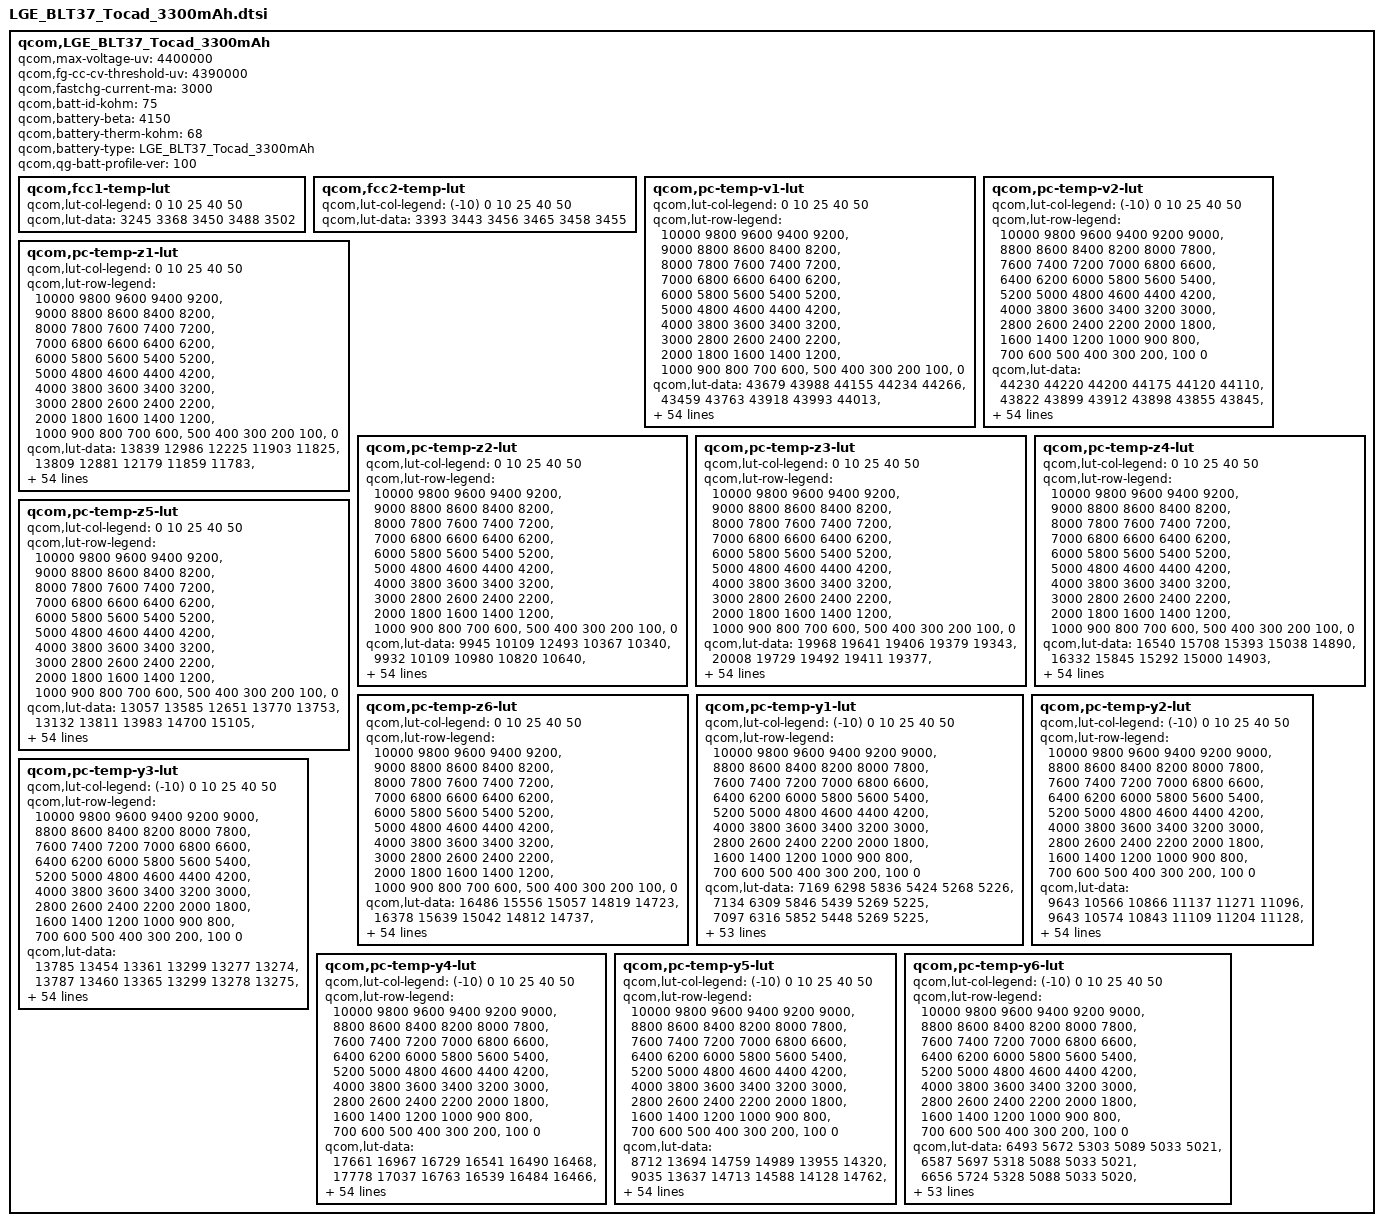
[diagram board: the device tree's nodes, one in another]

qcom,LGE_BLT37_Tocad_3300mAh {
    /* 3733478_LGE_CV7Atocad_3500mAh_averaged_MasterSlave_Dec3rd2018 */
    qcom,max-voltage-uv = <4400000>;
    qcom,fg-cc-cv-threshold-uv = <4390000>;
    qcom,fastchg-current-ma = <3000>;
    qcom,batt-id-kohm = <75>;
    qcom,battery-beta = <4150>;
    qcom,battery-therm-kohm = <68>;
    qcom,battery-type = "LGE_BLT37_Tocad_3300mAh";
    qcom,qg-batt-profile-ver = <100>;

	qcom,fcc1-temp-lut {
		qcom,lut-col-legend = <0 10 25 40 50>;
		qcom,lut-data = <3245 3368 3450 3488 3502>;
	};

	qcom,fcc2-temp-lut {
		qcom,lut-col-legend = <(-10) 0 10 25 40 50>;
		qcom,lut-data = <3393 3443 3456 3465 3458 3455>;
	};

	qcom,pc-temp-v1-lut {
		qcom,lut-col-legend = <0 10 25 40 50>;
		qcom,lut-row-legend = <10000 9800 9600 9400 9200>,
			<9000 8800 8600 8400 8200>,
			<8000 7800 7600 7400 7200>,
			<7000 6800 6600 6400 6200>,
			<6000 5800 5600 5400 5200>,
			<5000 4800 4600 4400 4200>,
			<4000 3800 3600 3400 3200>,
			<3000 2800 2600 2400 2200>,
			<2000 1800 1600 1400 1200>,
			<1000 900 800 700 600>,
			<500 400 300 200 100>,
			<0>;
		qcom,lut-data = <43679 43988 44155 44234 44266>,
			<43459 43763 43918 43993 44013>,
			<43231 43543 43686 43758 43776>,
			<42996 43321 43462 43531 43548>,
			<42760 43090 43238 43311 43329>,
			<42526 42851 43004 43084 43107>,
			<42292 42613 42764 42846 42875>,
			<42063 42372 42523 42604 42638>,
			<41839 42133 42280 42362 42399>,
			<41620 41900 42039 42120 42156>,
			<41405 41671 41803 41881 41915>,
			<41194 41449 41569 41644 41679>,
			<40989 41230 41343 41412 41448>,
			<40790 41019 41124 41187 41221>,
			<40594 40812 40911 40969 40999>,
			<40405 40611 40706 40758 40784>,
			<40223 40419 40507 40554 40579>,
			<40048 40248 40317 40357 40381>,
			<39887 40091 40141 40174 40194>,
			<39746 39927 39971 40002 40019>,
			<39606 39754 39792 39822 39840>,
			<39447 39569 39601 39617 39638>,
			<39275 39349 39404 39405 39428>,
			<39104 39078 39185 39209 39232>,
			<38931 38867 38965 39020 39043>,
			<38764 38756 38816 38862 38879>,
			<38643 38673 38722 38738 38747>,
			<38557 38597 38641 38633 38634>,
			<38490 38527 38551 38534 38531>,
			<38435 38461 38462 38441 38437>,
			<38390 38398 38385 38357 38350>,
			<38351 38338 38315 38281 38269>,
			<38315 38284 38253 38211 38194>,
			<38281 38234 38198 38150 38128>,
			<38249 38189 38149 38098 38071>,
			<38219 38151 38102 38045 38011>,
			<38187 38120 38060 37988 37942>,
			<38142 38081 38015 37927 37866>,
			<38077 38014 37950 37856 37786>,
			<37996 37921 37862 37772 37702>,
			<37894 37819 37762 37675 37607>,
			<37764 37700 37648 37562 37493>,
			<37615 37561 37515 37429 37359>,
			<37450 37393 37350 37267 37194>,
			<37312 37234 37195 37117 37046>,
			<37208 37131 37094 37022 36961>,
			<37169 37103 37069 37000 36938>,
			<37138 37084 37048 36986 36922>,
			<37108 37056 37032 36968 36905>,
			<37051 37009 36988 36921 36854>,
			<36867 36812 36771 36673 36582>,
			<36432 36360 36332 36236 36144>,
			<35856 35773 35759 35660 35571>,
			<35059 34956 34979 34876 34786>,
			<33693 33554 33762 33655 33564>,
			<30000 30000 30000 30000 30000>;
	};

	qcom,pc-temp-v2-lut {
		qcom,lut-col-legend = <(-10) 0 10 25 40 50>;
		qcom,lut-row-legend = <10000 9800 9600 9400 9200 9000>,
			<8800 8600 8400 8200 8000 7800>,
			<7600 7400 7200 7000 6800 6600>,
			<6400 6200 6000 5800 5600 5400>,
			<5200 5000 4800 4600 4400 4200>,
			<4000 3800 3600 3400 3200 3000>,
			<2800 2600 2400 2200 2000 1800>,
			<1600 1400 1200 1000 900 800>,
			<700 600 500 400 300 200>,
			<100 0>;
		qcom,lut-data = <44230 44220 44200 44175 44120 44110>,
			<43822 43899 43912 43898 43855 43845>,
			<43472 43603 43642 43635 43600 43591>,
			<43195 43337 43390 43389 43359 43351>,
			<42984 43102 43160 43163 43133 43125>,
			<42776 42869 42930 42936 42905 42899>,
			<42520 42625 42688 42697 42668 42663>,
			<42242 42379 42443 42455 42428 42424>,
			<41983 42132 42200 42213 42188 42185>,
			<41740 41887 41959 41972 41949 41947>,
			<41518 41641 41722 41735 41713 41712>,
			<41338 41384 41488 41503 41483 41481>,
			<41189 41127 41259 41276 41257 41255>,
			<41006 40915 41038 41054 41037 41034>,
			<40730 40757 40824 40835 40820 40819>,
			<40406 40597 40616 40624 40611 40611>,
			<40105 40383 40415 40421 40410 40411>,
			<39811 40127 40217 40225 40217 40218>,
			<39538 39877 40009 40036 40030 40032>,
			<39298 39635 39784 39859 39858 39860>,
			<39076 39400 39555 39674 39679 39682>,
			<38862 39181 39331 39445 39456 39461>,
			<38643 38973 39108 39189 39203 39210>,
			<38465 38785 38917 38980 38996 39003>,
			<38353 38617 38757 38817 38837 38845>,
			<38269 38463 38616 38676 38700 38711>,
			<38200 38318 38489 38554 38578 38589>,
			<38141 38178 38376 38446 38472 38481>,
			<38087 38075 38271 38348 38375 38383>,
			<38034 38015 38172 38257 38285 38291>,
			<37983 37968 38082 38174 38203 38206>,
			<37932 37922 37995 38097 38128 38129>,
			<37879 37878 37911 38025 38059 38058>,
			<37824 37834 37845 37957 37991 37986>,
			<37768 37789 37804 37892 37921 37911>,
			<37710 37743 37768 37826 37848 37830>,
			<37649 37691 37726 37752 37758 37731>,
			<37585 37632 37680 37670 37648 37606>,
			<37515 37563 37623 37588 37545 37491>,
			<37438 37481 37549 37511 37458 37402>,
			<37350 37383 37457 37431 37375 37319>,
			<37254 37270 37346 37333 37275 37219>,
			<37152 37131 37207 37212 37156 37097>,
			<37047 36984 37054 37062 37014 36958>,
			<36949 36830 36897 36924 36879 36825>,
			<36856 36729 36794 36880 36848 36796>,
			<36811 36696 36759 36865 36834 36783>,
			<36767 36665 36725 36846 36820 36765>,
			<36720 36616 36675 36817 36790 36735>,
			<36666 36544 36591 36740 36708 36638>,
			<36591 36365 36365 36470 36416 36326>,
			<36426 35956 35907 35988 35933 35837>,
			<36063 35269 35269 35357 35294 35193>,
			<35408 34234 34398 34480 34412 34299>,
			<34365 32611 33014 33140 33063 32918>,
			<32811 29064 27778 28286 28226 28233>;
	};

	qcom,pc-temp-z1-lut {
		qcom,lut-col-legend = <0 10 25 40 50>;
		qcom,lut-row-legend = <10000 9800 9600 9400 9200>,
			<9000 8800 8600 8400 8200>,
			<8000 7800 7600 7400 7200>,
			<7000 6800 6600 6400 6200>,
			<6000 5800 5600 5400 5200>,
			<5000 4800 4600 4400 4200>,
			<4000 3800 3600 3400 3200>,
			<3000 2800 2600 2400 2200>,
			<2000 1800 1600 1400 1200>,
			<1000 900 800 700 600>,
			<500 400 300 200 100>,
			<0>;
		qcom,lut-data = <13839 12986 12225 11903 11825>,
			<13809 12881 12179 11859 11783>,
			<13792 12850 12146 11829 11756>,
			<13780 12833 12124 11816 11747>,
			<13770 12827 12108 11808 11742>,
			<13756 12821 12097 11804 11740>,
			<13736 12814 12088 11802 11740>,
			<13717 12790 12081 11801 11740>,
			<13699 12762 12077 11800 11740>,
			<13681 12755 12074 11800 11741>,
			<13666 12754 12072 11800 11741>,
			<13651 12753 12071 11800 11742>,
			<13639 12751 12070 11801 11743>,
			<13641 12746 12071 11802 11745>,
			<13655 12744 12073 11803 11747>,
			<13663 12743 12075 11805 11750>,
			<13649 12742 12078 11808 11752>,
			<13629 12743 12080 11811 11754>,
			<13625 12747 12081 11812 11756>,
			<13641 12752 12083 11813 11760>,
			<13659 12766 12085 11815 11763>,
			<13664 12780 12089 11818 11765>,
			<13666 12781 12094 11823 11767>,
			<13666 12775 12098 11827 11770>,
			<13664 12772 12103 11830 11774>,
			<13659 12773 12108 11833 11778>,
			<13659 12777 12112 11838 11782>,
			<13673 12781 12117 11843 11785>,
			<13691 12790 12122 11847 11788>,
			<13700 12799 12128 11851 11791>,
			<13706 12803 12134 11855 11794>,
			<13708 12806 12139 11859 11798>,
			<13703 12807 12144 11862 11801>,
			<13691 12805 12148 11866 11804>,
			<13690 12803 12152 11870 11806>,
			<13701 12808 12157 11874 11809>,
			<13717 12828 12161 11876 11812>,
			<13737 12842 12165 11879 11814>,
			<13774 12843 12169 11882 11816>,
			<13800 12843 12173 11884 11817>,
			<13787 12844 12177 11887 11819>,
			<13758 12849 12183 11890 11823>,
			<13754 12857 12190 11894 11828>,
			<13757 12877 12196 11898 11830>,
			<13784 12873 12205 11904 11833>,
			<13761 12870 12207 11905 11834>,
			<13756 12880 12210 11905 11835>,
			<13759 12876 12212 11907 11831>,
			<13757 12880 12212 11908 11835>,
			<13777 12874 12218 11911 11839>,
			<13819 12893 12232 11917 11844>,
			<13809 12901 12254 11928 11852>,
			<13823 12941 12261 11941 11864>,
			<13867 12987 12295 11962 11880>,
			<13867 12987 12295 11962 11880>,
			<13867 12987 12295 11962 11880>;
	};

	qcom,pc-temp-z2-lut {
		qcom,lut-col-legend = <0 10 25 40 50>;
		qcom,lut-row-legend = <10000 9800 9600 9400 9200>,
			<9000 8800 8600 8400 8200>,
			<8000 7800 7600 7400 7200>,
			<7000 6800 6600 6400 6200>,
			<6000 5800 5600 5400 5200>,
			<5000 4800 4600 4400 4200>,
			<4000 3800 3600 3400 3200>,
			<3000 2800 2600 2400 2200>,
			<2000 1800 1600 1400 1200>,
			<1000 900 800 700 600>,
			<500 400 300 200 100>,
			<0>;
		qcom,lut-data = <9945 10109 12493 10367 10340>,
			<9932 10109 10980 10820 10640>,
			<9922 10079 10303 11078 11106>,
			<9913 10040 10249 11061 11229>,
			<9905 10013 10205 10860 11118>,
			<9898 9988 10177 10740 10997>,
			<9893 9969 10153 10740 10942>,
			<9887 9955 10144 10742 10893>,
			<9878 9945 10220 10690 10802>,
			<9868 9948 10345 10468 10489>,
			<9861 9969 10394 10336 10250>,
			<9855 9992 10417 10498 10391>,
			<9851 10007 10430 10728 10699>,
			<9853 10020 10434 10754 10815>,
			<9862 10031 10433 10707 10854>,
			<9872 10040 10438 10681 10882>,
			<9878 10050 10463 10704 10748>,
			<9885 10078 10484 10738 10463>,
			<9893 10132 10438 10703 10382>,
			<9904 10158 10345 10493 10375>,
			<9915 10137 10322 10372 10375>,
			<9923 10109 10335 10451 10388>,
			<9930 10105 10345 10551 10412>,
			<9937 10110 10326 10545 10447>,
			<9946 10112 10285 10452 10522>,
			<9954 10111 10277 10399 10568>,
			<9962 10109 10335 10468 10549>,
			<9969 10110 10388 10560 10501>,
			<9976 10116 10384 10552 10438>,
			<9982 10123 10361 10456 10332>,
			<9989 10127 10346 10397 10270>,
			<9995 10130 10322 10400 10279>,
			<10001 10133 10301 10406 10301>,
			<10007 10138 10309 10415 10330>,
			<10012 10143 10336 10443 10378>,
			<10017 10149 10361 10473 10433>,
			<10022 10155 10377 10530 10505>,
			<10030 10162 10393 10603 10575>,
			<10042 10174 10415 10634 10594>,
			<10055 10189 10445 10656 10595>,
			<10066 10198 10465 10666 10596>,
			<10078 10202 10475 10661 10601>,
			<10095 10209 10481 10650 10607>,
			<10127 10225 10483 10612 10595>,
			<10362 10353 10530 10600 10585>,
			<10203 10396 10530 10590 10599>,
			<10184 10461 10529 10546 10633>,
			<10074 10724 10502 10548 10576>,
			<9983 10821 10475 10562 10638>,
			<9891 10897 10527 10637 10742>,
			<9767 10810 10765 10586 10450>,
			<9747 10705 10780 10490 10342>,
			<9735 10566 10786 10446 10381>,
			<9714 10332 10830 10350 10337>,
			<9714 10332 10830 10350 10337>,
			<9714 10332 10830 10350 10337>;
	};

	qcom,pc-temp-z3-lut {
		qcom,lut-col-legend = <0 10 25 40 50>;
		qcom,lut-row-legend = <10000 9800 9600 9400 9200>,
			<9000 8800 8600 8400 8200>,
			<8000 7800 7600 7400 7200>,
			<7000 6800 6600 6400 6200>,
			<6000 5800 5600 5400 5200>,
			<5000 4800 4600 4400 4200>,
			<4000 3800 3600 3400 3200>,
			<3000 2800 2600 2400 2200>,
			<2000 1800 1600 1400 1200>,
			<1000 900 800 700 600>,
			<500 400 300 200 100>,
			<0>;
		qcom,lut-data = <19968 19641 19406 19379 19343>,
			<20008 19729 19492 19411 19377>,
			<20035 19763 19539 19435 19397>,
			<20057 19779 19556 19451 19412>,
			<20068 19779 19566 19466 19430>,
			<20064 19778 19566 19473 19439>,
			<20055 19777 19562 19471 19432>,
			<20051 19775 19557 19467 19419>,
			<20050 19771 19557 19459 19408>,
			<20049 19762 19557 19433 19392>,
			<20050 19737 19552 19416 19379>,
			<20055 19715 19543 19422 19380>,
			<20058 19704 19532 19433 19386>,
			<20055 19696 19519 19429 19386>,
			<20044 19689 19504 19414 19384>,
			<20030 19683 19496 19404 19381>,
			<20008 19678 19492 19401 19368>,
			<19983 19677 19488 19399 19349>,
			<19969 19680 19476 19393 19341>,
			<19960 19682 19461 19378 19339>,
			<19955 19673 19459 19369 19338>,
			<19958 19663 19476 19382 19345>,
			<19970 19668 19490 19399 19358>,
			<19979 19692 19486 19395 19357>,
			<19980 19707 19476 19364 19341>,
			<19980 19697 19466 19346 19330>,
			<19978 19677 19451 19375 19354>,
			<19971 19668 19440 19415 19392>,
			<19960 19663 19456 19422 19399>,
			<19950 19660 19495 19419 19386>,
			<19939 19663 19509 19416 19374>,
			<19928 19669 19504 19409 19368>,
			<19918 19672 19498 19400 19364>,
			<19909 19671 19491 19392 19358>,
			<19902 19667 19483 19384 19350>,
			<19895 19663 19477 19379 19346>,
			<19889 19656 19471 19378 19347>,
			<19880 19648 19467 19378 19348>,
			<19868 19642 19463 19377 19348>,
			<19853 19636 19459 19372 19347>,
			<19837 19629 19455 19369 19346>,
			<19817 19620 19451 19368 19344>,
			<19795 19609 19446 19366 19342>,
			<19760 19591 19438 19359 19344>,
			<19473 19540 19421 19352 19344>,
			<19347 19514 19415 19352 19329>,
			<19340 19473 19407 19351 19329>,
			<19309 19352 19410 19342 19328>,
			<19291 19329 19390 19340 19323>,
			<19282 19321 19386 19338 19319>,
			<19270 19334 19349 19350 19350>,
			<19278 19325 19349 19355 19353>,
			<19307 19326 19335 19360 19338>,
			<19387 19349 19326 19362 19339>,
			<19387 19349 19326 19362 19339>,
			<19387 19349 19326 19362 19339>;
	};

	qcom,pc-temp-z4-lut {
		qcom,lut-col-legend = <0 10 25 40 50>;
		qcom,lut-row-legend = <10000 9800 9600 9400 9200>,
			<9000 8800 8600 8400 8200>,
			<8000 7800 7600 7400 7200>,
			<7000 6800 6600 6400 6200>,
			<6000 5800 5600 5400 5200>,
			<5000 4800 4600 4400 4200>,
			<4000 3800 3600 3400 3200>,
			<3000 2800 2600 2400 2200>,
			<2000 1800 1600 1400 1200>,
			<1000 900 800 700 600>,
			<500 400 300 200 100>,
			<0>;
		qcom,lut-data = <16540 15708 15393 15038 14890>,
			<16332 15845 15292 15000 14903>,
			<16126 15658 15200 14960 14882>,
			<15913 15426 15113 14917 14855>,
			<15730 15298 15035 14871 14814>,
			<15597 15201 14976 14832 14780>,
			<15489 15124 14930 14795 14763>,
			<15396 15058 14888 14767 14750>,
			<15313 15004 14843 14762 14745>,
			<15240 14964 14804 14773 14752>,
			<15171 14933 14783 14778 14758>,
			<15105 14909 14770 14752 14744>,
			<15048 14892 14762 14718 14718>,
			<14999 14879 14759 14710 14702>,
			<14954 14870 14755 14708 14690>,
			<14934 14864 14750 14705 14682>,
			<14940 14858 14740 14695 14684>,
			<14950 14838 14732 14683 14694>,
			<14950 14798 14733 14678 14694>,
			<14922 14779 14742 14684 14687>,
			<14892 14792 14752 14696 14682>,
			<14891 14818 14763 14716 14697>,
			<14899 14860 14780 14746 14733>,
			<14913 14955 14843 14794 14774>,
			<14952 15013 14941 14876 14831>,
			<15011 15009 14969 14917 14863>,
			<15032 14998 14959 14875 14826>,
			<15030 14984 14941 14808 14762>,
			<15026 14962 14903 14775 14738>,
			<15019 14936 14841 14755 14731>,
			<15000 14912 14807 14742 14724>,
			<14979 14888 14793 14731 14714>,
			<14960 14871 14784 14724 14703>,
			<14942 14862 14780 14720 14698>,
			<14925 14854 14778 14717 14695>,
			<14908 14846 14777 14716 14693>,
			<14892 14837 14779 14724 14706>,
			<14876 14831 14782 14738 14727>,
			<14861 14831 14789 14747 14731>,
			<14848 14830 14800 14756 14731>,
			<14837 14827 14804 14759 14730>,
			<14828 14802 14789 14750 14723>,
			<14810 14780 14772 14741 14717>,
			<14793 14767 14765 14745 14718>,
			<14948 14735 14739 14736 14710>,
			<15079 14727 14718 14716 14707>,
			<15079 14760 14705 14701 14690>,
			<15100 14877 14684 14683 14669>,
			<15110 14894 14684 14664 14652>,
			<15105 14898 14684 14665 14656>,
			<15118 14887 14750 14684 14653>,
			<15135 14915 14757 14680 14651>,
			<15126 14923 14772 14672 14667>,
			<15089 14921 14783 14669 14661>,
			<15089 14921 14783 14669 14661>,
			<15089 14921 14783 14669 14661>;
	};

	qcom,pc-temp-z5-lut {
		qcom,lut-col-legend = <0 10 25 40 50>;
		qcom,lut-row-legend = <10000 9800 9600 9400 9200>,
			<9000 8800 8600 8400 8200>,
			<8000 7800 7600 7400 7200>,
			<7000 6800 6600 6400 6200>,
			<6000 5800 5600 5400 5200>,
			<5000 4800 4600 4400 4200>,
			<4000 3800 3600 3400 3200>,
			<3000 2800 2600 2400 2200>,
			<2000 1800 1600 1400 1200>,
			<1000 900 800 700 600>,
			<500 400 300 200 100>,
			<0>;
		qcom,lut-data = <13057 13585 12651 13770 13753>,
			<13132 13811 13983 14700 15105>,
			<13274 14202 14836 15538 16133>,
			<13550 14614 15293 16186 17140>,
			<13836 14890 15638 16907 18698>,
			<14045 15110 15905 17772 19906>,
			<14250 15391 16129 19175 20044>,
			<14487 15869 16476 20480 19905>,
			<14775 16402 17545 20240 19744>,
			<15137 16763 18954 18266 18340>,
			<15628 17021 19794 17100 17163>,
			<16381 17290 20454 19260 17882>,
			<17322 17633 20729 22348 19727>,
			<18611 18035 20325 22616 21289>,
			<20311 18504 19721 21613 22892>,
			<21151 19152 19688 21063 23809>,
			<20650 19680 20397 22192 21974>,
			<19825 19804 21052 23914 18332>,
			<19623 19766 20722 23874 17427>,
			<20292 19912 19902 21290 17962>,
			<21534 21388 20532 20018 18795>,
			<24055 23886 24889 23581 20733>,
			<29334 26835 28302 28079 23068>,
			<33263 30987 26936 26977 22616>,
			<34506 33316 23353 19225 17362>,
			<35331 30516 20500 14709 13744>,
			<35461 25244 17739 15474 15293>,
			<33912 22933 16004 16871 17901>,
			<31704 22105 16917 17958 18446>,
			<30259 21698 19574 18902 18264>,
			<29066 22241 21777 19859 18132>,
			<28297 24023 23454 20940 18852>,
			<27992 25780 24906 21999 20243>,
			<27773 27588 26191 22847 21168>,
			<27714 29069 27400 23637 21905>,
			<28043 29443 27798 23997 22255>,
			<28586 29585 27731 24006 22132>,
			<29054 29657 27579 23981 21820>,
			<29649 29684 26816 23499 21328>,
			<30056 29650 24784 21271 20288>,
			<29317 29452 23700 19641 19376>,
			<27464 28796 23662 19484 18910>,
			<26723 27787 23558 19331 18556>,
			<26005 26125 21904 17759 18089>,
			<14487 25274 22205 17598 18255>,
			<11633 22470 23144 18457 16587>,
			<11537 18693 22066 19126 17451>,
			<11310 12254 24118 19204 19304>,
			<11170 11868 20110 21265 21650>,
			<11128 11761 19594 20470 19676>,
			<11081 12046 14088 17307 21712>,
			<11072 11766 13610 17312 22001>,
			<11160 11705 12852 18009 18609>,
			<12164 12293 12448 17639 16896>,
			<12164 12293 12448 17639 16896>,
			<12164 12293 12448 17639 16896>;
	};

	qcom,pc-temp-z6-lut {
		qcom,lut-col-legend = <0 10 25 40 50>;
		qcom,lut-row-legend = <10000 9800 9600 9400 9200>,
			<9000 8800 8600 8400 8200>,
			<8000 7800 7600 7400 7200>,
			<7000 6800 6600 6400 6200>,
			<6000 5800 5600 5400 5200>,
			<5000 4800 4600 4400 4200>,
			<4000 3800 3600 3400 3200>,
			<3000 2800 2600 2400 2200>,
			<2000 1800 1600 1400 1200>,
			<1000 900 800 700 600>,
			<500 400 300 200 100>,
			<0>;
		qcom,lut-data = <16486 15556 15057 14819 14723>,
			<16378 15639 15042 14812 14737>,
			<16273 15556 15024 14804 14737>,
			<16166 15451 14995 14793 14734>,
			<16070 15386 14959 14779 14726>,
			<15993 15333 14930 14765 14715>,
			<15927 15288 14905 14750 14704>,
			<15871 15252 14884 14736 14692>,
			<15824 15221 14864 14725 14683>,
			<15784 15191 14847 14717 14677>,
			<15747 15161 14833 14709 14672>,
			<15714 15139 14823 14702 14665>,
			<15683 15124 14813 14694 14659>,
			<15654 15114 14804 14686 14652>,
			<15626 15106 14795 14678 14647>,
			<15607 15099 14788 14671 14641>,
			<15599 15093 14782 14665 14635>,
			<15593 15082 14776 14660 14629>,
			<15584 15067 14772 14655 14624>,
			<15569 15061 14768 14651 14620>,
			<15557 15064 14769 14650 14618>,
			<15558 15072 14781 14663 14628>,
			<15571 15093 14800 14687 14651>,
			<15587 15148 14829 14707 14669>,
			<15609 15183 14864 14727 14687>,
			<15634 15177 14872 14736 14696>,
			<15642 15165 14862 14733 14693>,
			<15640 15154 14850 14726 14687>,
			<15635 15144 14843 14719 14680>,
			<15629 15134 14837 14710 14671>,
			<15617 15127 14831 14702 14662>,
			<15604 15122 14824 14694 14655>,
			<15593 15117 14817 14686 14648>,
			<15582 15113 14812 14680 14642>,
			<15573 15109 14807 14674 14637>,
			<15567 15105 14805 14671 14634>,
			<15562 15099 14805 14675 14640>,
			<15557 15097 14804 14681 14649>,
			<15552 15097 14805 14684 14651>,
			<15547 15098 14809 14686 14651>,
			<15542 15097 14811 14687 14650>,
			<15536 15086 14804 14683 14647>,
			<15527 15075 14795 14678 14643>,
			<15511 15066 14790 14677 14645>,
			<15439 15034 14773 14670 14643>,
			<15437 15021 14763 14661 14634>,
			<15437 15016 14753 14654 14627>,
			<15434 15007 14745 14642 14617>,
			<15431 15004 14737 14633 14606>,
			<15432 15005 14737 14633 14606>,
			<15442 15015 14748 14648 14623>,
			<15468 15029 14756 14652 14626>,
			<15496 15045 14759 14655 14627>,
			<15546 15076 14767 14658 14630>,
			<15546 15076 14767 14658 14630>,
			<15546 15076 14767 14658 14630>;
	};

	qcom,pc-temp-y1-lut {
		qcom,lut-col-legend = <(-10) 0 10 25 40 50>;
		qcom,lut-row-legend = <10000 9800 9600 9400 9200 9000>,
			<8800 8600 8400 8200 8000 7800>,
			<7600 7400 7200 7000 6800 6600>,
			<6400 6200 6000 5800 5600 5400>,
			<5200 5000 4800 4600 4400 4200>,
			<4000 3800 3600 3400 3200 3000>,
			<2800 2600 2400 2200 2000 1800>,
			<1600 1400 1200 1000 900 800>,
			<700 600 500 400 300 200>,
			<100 0>;
		qcom,lut-data = <7169 6298 5836 5424 5268 5226>,
			<7134 6309 5846 5439 5269 5225>,
			<7097 6316 5852 5448 5269 5225>,
			<7063 6320 5855 5453 5269 5224>,
			<7038 6323 5856 5454 5268 5224>,
			<7027 6323 5856 5453 5267 5224>,
			<7031 6320 5853 5448 5265 5224>,
			<7042 6315 5847 5439 5262 5225>,
			<7047 6315 5846 5436 5261 5225>,
			<7053 6321 5848 5435 5262 5225>,
			<7059 6326 5850 5435 5263 5225>,
			<7062 6325 5850 5435 5264 5226>,
			<7060 6321 5849 5434 5265 5227>,
			<7061 6321 5847 5434 5265 5228>,
			<7065 6323 5841 5434 5265 5229>,
			<7070 6326 5837 5434 5264 5230>,
			<7075 6330 5838 5435 5266 5231>,
			<7088 6336 5842 5435 5269 5231>,
			<7096 6344 5845 5437 5271 5232>,
			<7090 6354 5849 5441 5269 5235>,
			<7081 6363 5853 5444 5266 5237>,
			<7079 6367 5852 5445 5268 5238>,
			<7075 6373 5851 5446 5273 5239>,
			<7070 6375 5850 5446 5277 5239>,
			<7069 6374 5852 5448 5279 5241>,
			<7067 6374 5854 5450 5281 5243>,
			<7068 6371 5857 5453 5283 5244>,
			<7079 6359 5866 5457 5287 5246>,
			<7089 6351 5871 5461 5289 5247>,
			<7088 6359 5873 5466 5290 5250>,
			<7087 6371 5875 5470 5292 5254>,
			<7088 6371 5876 5473 5294 5255>,
			<7102 6364 5879 5477 5298 5256>,
			<7122 6359 5884 5480 5300 5257>,
			<7124 6362 5889 5483 5301 5259>,
			<7097 6367 5894 5486 5302 5261>,
			<7075 6372 5898 5489 5304 5264>,
			<7077 6381 5905 5494 5308 5266>,
			<7082 6388 5910 5498 5311 5268>,
			<7084 6389 5913 5501 5313 5269>,
			<7085 6390 5916 5505 5315 5270>,
			<7086 6394 5918 5508 5317 5271>,
			<7098 6412 5920 5512 5318 5274>,
			<7124 6423 5922 5516 5319 5275>,
			<7136 6422 5922 5519 5322 5275>,
			<7154 6460 5928 5523 5326 5279>,
			<7155 6449 5928 5529 5327 5280>,
			<7126 6435 5929 5527 5325 5279>,
			<7217 6448 5933 5532 5327 5280>,
			<7169 6455 5938 5530 5327 5282>,
			<7232 6497 5946 5533 5333 5293>,
			<7322 6573 5969 5547 5340 5295>,
			<7382 6632 6024 5567 5346 5299>,
			<7304 6611 6140 5595 5360 5311>,
			<7304 6611 6140 5595 5360 5311>,
			<7304 6611 6140 5595 5360 5311>;
	};

	qcom,pc-temp-y2-lut {
		qcom,lut-col-legend = <(-10) 0 10 25 40 50>;
		qcom,lut-row-legend = <10000 9800 9600 9400 9200 9000>,
			<8800 8600 8400 8200 8000 7800>,
			<7600 7400 7200 7000 6800 6600>,
			<6400 6200 6000 5800 5600 5400>,
			<5200 5000 4800 4600 4400 4200>,
			<4000 3800 3600 3400 3200 3000>,
			<2800 2600 2400 2200 2000 1800>,
			<1600 1400 1200 1000 900 800>,
			<700 600 500 400 300 200>,
			<100 0>;
		qcom,lut-data = <9643 10566 10866 11137 11271 11096>,
			<9643 10574 10843 11109 11204 11128>,
			<9643 10577 10820 11080 11127 11134>,
			<9828 10578 10796 11050 11052 11120>,
			<10112 10577 10772 11021 10989 11091>,
			<10253 10575 10749 10994 10947 11055>,
			<10244 10566 10724 10964 10924 10992>,
			<10219 10551 10700 10936 10908 10918>,
			<10220 10546 10685 10930 10905 10902>,
			<10384 10545 10674 10942 10930 10913>,
			<10553 10544 10669 10951 10951 10922>,
			<10520 10556 10670 10934 10944 10917>,
			<10372 10583 10675 10905 10928 10906>,
			<10299 10596 10683 10899 10930 10904>,
			<10384 10593 10710 10913 10969 10917>,
			<10496 10591 10743 10934 11006 10930>,
			<10423 10617 10776 10957 11007 10934>,
			<9984 10675 10810 10986 10997 10941>,
			<9681 10697 10829 11018 11006 10966>,
			<9672 10693 10838 11062 11101 11046>,
			<9669 10688 10843 11092 11191 11123>,
			<9666 10688 10844 11086 11177 11142>,
			<9664 10693 10843 11067 11130 11152>,
			<9662 10695 10845 11058 11115 11168>,
			<9661 10695 10871 11059 11159 11202>,
			<9660 10694 10899 11065 11213 11245>,
			<9659 10633 10901 11095 11226 11283>,
			<9658 10420 10899 11160 11222 11321>,
			<9657 10303 10896 11190 11229 11351>,
			<9656 10282 10889 11190 11294 11378>,
			<9655 10249 10881 11189 11372 11400>,
			<9655 10185 10891 11195 11406 11405>,
			<9654 9987 10921 11208 11429 11395>,
			<9654 9828 10937 11213 11438 11387>,
			<9654 9766 10916 11185 11437 11389>,
			<9654 9703 10876 11149 11427 11396>,
			<9654 9679 10838 11137 11394 11392>,
			<9653 9669 10798 11132 11326 11357>,
			<9653 9663 10749 11127 11287 11331>,
			<9653 9660 10683 11130 11296 11338>,
			<9653 9657 10603 11137 11311 11355>,
			<9653 9656 10513 11133 11300 11349>,
			<9653 9655 10406 11121 11272 11276>,
			<9653 9654 10316 11098 11258 11260>,
			<9653 9653 10225 11050 11245 11296>,
			<9653 9652 9845 10977 11212 11221>,
			<9652 9652 9830 11012 11176 11194>,
			<9652 9652 9760 11002 11171 11103>,
			<9651 9651 9708 10981 11076 11025>,
			<9651 9651 9676 10951 11099 11021>,
			<9649 9650 9664 10911 11094 11032>,
			<9648 9649 9656 10847 11014 10977>,
			<9647 9647 9652 10764 10951 10896>,
			<9647 9647 9649 10675 10847 10779>,
			<9647 9647 9649 10675 10847 10779>,
			<9647 9647 9649 10675 10847 10779>;
	};

	qcom,pc-temp-y3-lut {
		qcom,lut-col-legend = <(-10) 0 10 25 40 50>;
		qcom,lut-row-legend = <10000 9800 9600 9400 9200 9000>,
			<8800 8600 8400 8200 8000 7800>,
			<7600 7400 7200 7000 6800 6600>,
			<6400 6200 6000 5800 5600 5400>,
			<5200 5000 4800 4600 4400 4200>,
			<4000 3800 3600 3400 3200 3000>,
			<2800 2600 2400 2200 2000 1800>,
			<1600 1400 1200 1000 900 800>,
			<700 600 500 400 300 200>,
			<100 0>;
		qcom,lut-data = <13785 13454 13361 13299 13277 13274>,
			<13787 13460 13365 13299 13278 13275>,
			<13785 13466 13368 13299 13279 13275>,
			<13780 13472 13371 13300 13280 13276>,
			<13773 13477 13374 13300 13281 13277>,
			<13765 13482 13377 13300 13282 13278>,
			<13754 13488 13379 13300 13283 13279>,
			<13740 13493 13382 13301 13283 13280>,
			<13737 13494 13384 13301 13284 13280>,
			<13764 13494 13386 13300 13284 13281>,
			<13791 13493 13387 13300 13285 13282>,
			<13759 13488 13388 13303 13287 13282>,
			<13650 13476 13388 13310 13291 13282>,
			<13595 13464 13387 13312 13293 13282>,
			<13613 13450 13386 13310 13292 13283>,
			<13636 13440 13383 13309 13291 13283>,
			<13639 13442 13381 13310 13291 13284>,
			<13633 13449 13380 13313 13291 13284>,
			<13625 13452 13377 13316 13292 13285>,
			<13617 13441 13372 13318 13296 13287>,
			<13606 13426 13366 13320 13299 13289>,
			<13590 13417 13360 13317 13296 13287>,
			<13557 13410 13353 13310 13289 13280>,
			<13534 13404 13348 13304 13284 13276>,
			<13543 13398 13345 13298 13281 13275>,
			<13575 13392 13343 13295 13279 13275>,
			<13613 13372 13342 13295 13278 13275>,
			<13658 13326 13342 13296 13278 13275>,
			<13714 13302 13341 13297 13277 13275>,
			<13781 13304 13339 13297 13278 13276>,
			<13865 13308 13337 13298 13280 13277>,
			<13958 13316 13335 13299 13281 13277>,
			<14064 13339 13330 13300 13282 13276>,
			<14177 13365 13329 13300 13282 13276>,
			<14283 13390 13331 13300 13283 13276>,
			<14386 13422 13336 13299 13283 13276>,
			<14482 13458 13341 13298 13282 13275>,
			<14567 13500 13346 13296 13281 13274>,
			<14645 13552 13351 13295 13280 13273>,
			<14712 13628 13357 13294 13278 13273>,
			<14769 13732 13363 13293 13277 13274>,
			<14823 13851 13368 13294 13277 13274>,
			<14880 13994 13374 13295 13277 13274>,
			<14944 14175 13384 13296 13277 13274>,
			<15037 14418 13398 13297 13278 13274>,
			<15191 14714 13413 13303 13280 13277>,
			<15330 14774 13410 13303 13279 13277>,
			<15479 14890 13438 13305 13286 13278>,
			<15676 15132 13484 13310 13288 13284>,
			<16227 15424 13570 13316 13291 13283>,
			<17823 15954 13688 13313 13284 13282>,
			<22758 18204 13981 13319 13284 13284>,
			<36796 28628 14836 13331 13288 13285>,
			<65535 65535 17249 13342 13295 13286>,
			<65535 65535 17249 13342 13295 13286>,
			<65535 65535 17249 13342 13295 13286>;
	};

	qcom,pc-temp-y4-lut {
		qcom,lut-col-legend = <(-10) 0 10 25 40 50>;
		qcom,lut-row-legend = <10000 9800 9600 9400 9200 9000>,
			<8800 8600 8400 8200 8000 7800>,
			<7600 7400 7200 7000 6800 6600>,
			<6400 6200 6000 5800 5600 5400>,
			<5200 5000 4800 4600 4400 4200>,
			<4000 3800 3600 3400 3200 3000>,
			<2800 2600 2400 2200 2000 1800>,
			<1600 1400 1200 1000 900 800>,
			<700 600 500 400 300 200>,
			<100 0>;
		qcom,lut-data = <17661 16967 16729 16541 16490 16468>,
			<17778 17037 16763 16539 16484 16466>,
			<17907 17144 16793 16539 16481 16463>,
			<18027 17259 16819 16539 16479 16461>,
			<18118 17352 16836 16541 16478 16460>,
			<18160 17393 16843 16542 16478 16460>,
			<18151 17388 16837 16545 16479 16460>,
			<18120 17374 16825 16550 16482 16461>,
			<18079 17362 16820 16555 16486 16463>,
			<17989 17349 16818 16564 16491 16466>,
			<17912 17341 16817 16573 16495 16470>,
			<18018 17343 16822 16576 16498 16475>,
			<18371 17352 16837 16579 16500 16481>,
			<18545 17377 16859 16585 16504 16488>,
			<18296 17536 16902 16602 16515 16495>,
			<17915 17683 16949 16625 16529 16503>,
			<17728 17636 16988 16645 16542 16512>,
			<17626 17469 17024 16668 16558 16523>,
			<17534 17330 17031 16697 16577 16536>,
			<17430 17240 16992 16744 16607 16558>,
			<17326 17158 16931 16776 16629 16575>,
			<17226 17071 16857 16733 16607 16560>,
			<17118 16983 16765 16622 16546 16517>,
			<17045 16907 16708 16563 16509 16489>,
			<17025 16836 16677 16540 16493 16477>,
			<17014 16783 16657 16529 16484 16470>,
			<17012 16766 16648 16529 16484 16470>,
			<17022 16767 16642 16531 16490 16473>,
			<17037 16774 16636 16534 16496 16477>,
			<17048 16783 16630 16543 16504 16483>,
			<17057 16791 16623 16556 16514 16492>,
			<17065 16795 16608 16567 16526 16504>,
			<17074 16809 16580 16579 16542 16520>,
			<17082 16829 16567 16585 16551 16527>,
			<17092 16863 16576 16589 16554 16526>,
			<17102 16904 16594 16590 16556 16525>,
			<17113 16939 16617 16579 16548 16518>,
			<17124 16973 16649 16539 16515 16497>,
			<17133 16992 16682 16520 16493 16483>,
			<17135 16989 16714 16520 16490 16482>,
			<17127 16978 16744 16520 16489 16480>,
			<17115 16966 16767 16522 16487 16478>,
			<17101 16952 16786 16528 16486 16474>,
			<17088 16937 16796 16528 16479 16465>,
			<17092 16921 16804 16526 16464 16450>,
			<17119 16943 16848 16545 16481 16467>,
			<17145 16947 16838 16550 16496 16476>,
			<17152 16963 16876 16573 16500 16486>,
			<17150 17023 16945 16597 16513 16500>,
			<17187 17102 17044 16610 16518 16500>,
			<17339 17142 17092 16581 16484 16461>,
			<18141 17377 17119 16589 16483 16460>,
			<21212 21587 17250 16632 16493 16471>,
			<52336 65535 18044 16717 16528 16511>,
			<52336 65535 18044 16717 16528 16511>,
			<52336 65535 18044 16717 16528 16511>;
	};

	qcom,pc-temp-y5-lut {
		qcom,lut-col-legend = <(-10) 0 10 25 40 50>;
		qcom,lut-row-legend = <10000 9800 9600 9400 9200 9000>,
			<8800 8600 8400 8200 8000 7800>,
			<7600 7400 7200 7000 6800 6600>,
			<6400 6200 6000 5800 5600 5400>,
			<5200 5000 4800 4600 4400 4200>,
			<4000 3800 3600 3400 3200 3000>,
			<2800 2600 2400 2200 2000 1800>,
			<1600 1400 1200 1000 900 800>,
			<700 600 500 400 300 200>,
			<100 0>;
		qcom,lut-data = <8712 13694 14759 14989 13955 14320>,
			<9035 13637 14713 14588 14128 14762>,
			<10261 13625 14653 14198 14200 15101>,
			<11728 13649 14588 13832 14196 15339>,
			<12999 13697 14529 13506 14139 15481>,
			<13635 13762 14484 13233 14053 15531>,
			<13639 13874 14439 13021 13917 15469>,
			<13613 14006 14368 12837 13723 15317>,
			<13656 14027 14280 12615 13512 15145>,
			<14423 13893 14160 12302 13233 14880>,
			<15210 13664 14005 12115 13063 14560>,
			<15049 13131 13782 12319 13361 14163>,
			<14362 12327 13484 12715 13959 13711>,
			<14048 12109 13170 12784 14082 13455>,
			<15280 12647 12767 12432 13565 13382>,
			<16901 13432 12505 12136 13026 13386>,
			<16761 14196 12764 12162 12811 13274>,
			<14774 15038 13526 12275 12648 13008>,
			<13349 15520 14288 12476 12633 12993>,
			<13225 15723 15131 13091 12999 13269>,
			<13162 15878 15800 13910 13561 13601>,
			<12925 16093 16073 14868 14276 13849>,
			<11891 16341 16271 15929 15174 14075>,
			<11005 16438 16360 16197 15471 14346>,
			<10890 16424 16414 15400 15173 14809>,
			<10846 16389 16489 14619 14735 15178>,
			<10806 15616 16640 14661 14358 15074>,
			<10757 12744 16905 14924 13972 14660>,
			<10723 11086 17081 15170 13836 14389>,
			<10733 11110 17135 15401 14032 14414>,
			<10793 11186 17101 15678 14348 14534>,
			<10867 11226 16767 16060 14617 14513>,
			<10966 11288 15856 16565 14906 14333>,
			<11069 11360 15381 16939 15240 14274>,
			<11137 11487 15692 17256 15764 14682>,
			<11224 11639 16085 17529 16251 15186>,
			<11306 11734 16097 17560 16435 15230>,
			<11367 11791 15901 17222 16573 15075>,
			<11417 11837 15665 16875 16623 14984>,
			<11427 11892 15297 16057 16039 15059>,
			<11394 11949 14804 15193 15113 15164>,
			<11335 11941 14385 14993 14715 15144>,
			<11219 11737 14006 14875 14527 14958>,
			<11050 11571 13982 14836 14895 15391>,
			<10926 11476 14103 14827 15988 17153>,
			<10802 11336 12604 15063 14818 15153>,
			<10769 11364 12199 14784 13487 14128>,
			<10797 11442 12008 14097 14709 14133>,
			<10839 11373 11802 14107 14497 15410>,
			<10951 11455 11753 14402 14936 14911>,
			<10888 11343 11611 14549 14225 17025>,
			<10014 10710 11553 15651 14460 18200>,
			<9242 9327 11326 16621 15617 17956>,
			<8877 8828 10358 16472 17626 17889>,
			<8877 8828 10358 16472 17626 17889>,
			<8877 8828 10358 16472 17626 17889>;
	};

	qcom,pc-temp-y6-lut {
		qcom,lut-col-legend = <(-10) 0 10 25 40 50>;
		qcom,lut-row-legend = <10000 9800 9600 9400 9200 9000>,
			<8800 8600 8400 8200 8000 7800>,
			<7600 7400 7200 7000 6800 6600>,
			<6400 6200 6000 5800 5600 5400>,
			<5200 5000 4800 4600 4400 4200>,
			<4000 3800 3600 3400 3200 3000>,
			<2800 2600 2400 2200 2000 1800>,
			<1600 1400 1200 1000 900 800>,
			<700 600 500 400 300 200>,
			<100 0>;
		qcom,lut-data = <6493 5672 5303 5089 5033 5021>,
			<6587 5697 5318 5088 5033 5021>,
			<6656 5724 5328 5088 5033 5020>,
			<6703 5749 5333 5088 5033 5021>,
			<6731 5767 5336 5088 5033 5021>,
			<6741 5774 5337 5088 5034 5022>,
			<6726 5771 5334 5089 5035 5022>,
			<6690 5764 5328 5090 5036 5023>,
			<6668 5757 5324 5091 5038 5025>,
			<6656 5749 5322 5093 5039 5026>,
			<6649 5741 5321 5095 5041 5028>,
			<6657 5732 5321 5098 5044 5029>,
			<6684 5723 5323 5103 5047 5031>,
			<6698 5723 5327 5107 5050 5034>,
			<6655 5758 5337 5111 5053 5036>,
			<6580 5793 5348 5116 5056 5039>,
			<6516 5782 5356 5123 5059 5042>,
			<6452 5742 5364 5131 5064 5046>,
			<6404 5704 5365 5141 5070 5050>,
			<6376 5673 5351 5156 5081 5058>,
			<6355 5644 5328 5166 5090 5065>,
			<6334 5617 5303 5152 5082 5059>,
			<6308 5591 5273 5115 5059 5040>,
			<6293 5571 5254 5094 5045 5030>,
			<6304 5557 5245 5084 5038 5026>,
			<6341 5546 5239 5079 5034 5023>,
			<6383 5534 5239 5079 5034 5024>,
			<6432 5521 5238 5081 5035 5024>,
			<6490 5515 5238 5083 5037 5026>,
			<6556 5528 5238 5087 5040 5028>,
			<6633 5555 5237 5092 5044 5031>,
			<6715 5585 5235 5096 5048 5035>,
			<6802 5624 5228 5101 5054 5039>,
			<6892 5673 5225 5104 5057 5041>,
			<6977 5737 5232 5105 5059 5041>,
			<7059 5816 5246 5105 5059 5041>,
			<7134 5900 5261 5102 5057 5039>,
			<7202 5993 5282 5090 5047 5032>,
			<7264 6091 5306 5084 5040 5028>,
			<7315 6191 5335 5084 5039 5028>,
			<7355 6294 5369 5085 5038 5028>,
			<7394 6408 5406 5087 5037 5028>,
			<7436 6532 5447 5091 5037 5027>,
			<7484 6683 5499 5093 5036 5024>,
			<7565 6876 5564 5094 5032 5020>,
			<7708 7124 5641 5105 5039 5027>,
			<7829 7173 5629 5107 5042 5030>,
			<7951 7269 5692 5115 5048 5034>,
			<8111 7478 5795 5127 5053 5042>,
			<8568 7731 5942 5136 5057 5042>,
			<9884 8169 6120 5128 5043 5031>,
			<13842 9967 6442 5137 5044 5032>,
			<24495 18667 7208 5162 5051 5037>,
			<65535 65535 9328 5201 5067 5051>,
			<65535 65535 9328 5201 5067 5051>,
			<65535 65535 9328 5201 5067 5051>;
	};

};
